# STM32N645 register map
File version: 1.0
CPU: CM55 r0p1, little endian, no MPU, FPU, vendor SysTick, 8 interrupt priority bits
Registers are 32-bit, read-write, reset 0x0 unless marked. A register's access mark holds for its fields unless they carry their own. Offsets are from the block's base; [hi:lo] are bit positions; {n}, {i} and the like mark numbered series; 'fields as' and 'values as' point back to an identical list.

## LPTIM4 — Low-power timer
Base 0x46002C00
Same registers: LPTIM4_S 0x56002C00
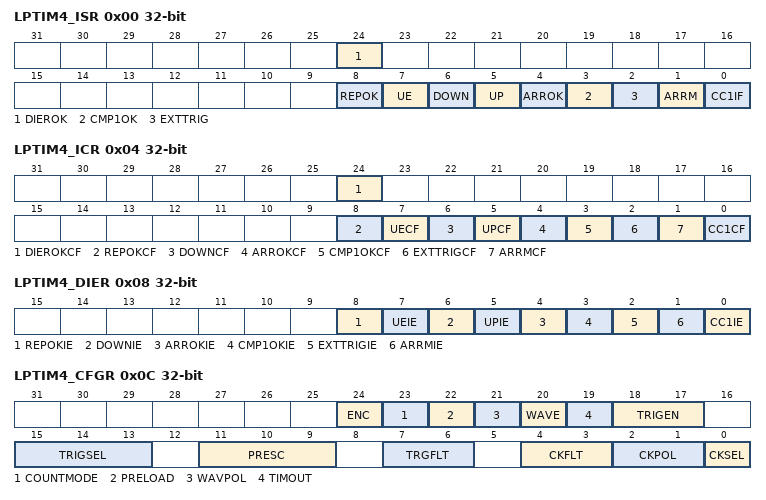
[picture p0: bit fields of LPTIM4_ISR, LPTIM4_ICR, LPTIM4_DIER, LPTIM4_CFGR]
0x00 LPTIM4_ISR ro — LPTIM4 interrupt and status register
  [24] DIEROK — Interrupt enable register update OK
  [8] REPOK — Repetition register update OK
  [7] UE — LPTIM update event occurred
  [6] DOWN — Counter direction change up to down
  [5] UP — Counter direction change down to up
  [4] ARROK — Autoreload register update OK
  [3] CMP1OK — Compare register 1 update OK
  [2] EXTTRIG — External trigger edge event
  [1] ARRM — Autoreload match
  [0] CC1IF — Compare 1 interrupt flag
    0=No match; 1=The content of the counter LPTIM_CNT register value has matched the LPTIM_CCR1 register's value
0x04 LPTIM4_ICR wo — LPTIM4 interrupt clear register
  [24] DIEROKCF — Interrupt enable register update OK clear flag
  [8] REPOKCF — Repetition register update OK clear flag
  [7] UECF — Update event clear flag
  [6] DOWNCF — Direction change to down clear flag
  [5] UPCF — Direction change to UP clear flag
  [4] ARROKCF — Autoreload register update OK clear flag
  [3] CMP1OKCF — Compare register 1 update OK clear flag
  [2] EXTTRIGCF — External trigger valid edge clear flag
  [1] ARRMCF — Autoreload match clear flag
  [0] CC1CF — Capture/compare 1 clear flag
0x08 LPTIM4_DIER — LPTIM4 interrupt enable register
  [8] REPOKIE — Repetition register update OK interrupt Enable
    0=Repetition register update OK interrupt disabled; 1=Repetition register update OK interrupt enabled
  [7] UEIE — Update event interrupt enable
    0=Update event interrupt disabled; 1=Update event interrupt enabled
  [6] DOWNIE — Direction change to down Interrupt Enable
    0=DOWN interrupt disabled; 1=DOWN interrupt enabled
  [5] UPIE — Direction change to UP Interrupt Enable
    0=UP interrupt disabled; 1=UP interrupt enabled
  [4] ARROKIE — Autoreload register update OK Interrupt Enable
    0=ARROK interrupt disabled; 1=ARROK interrupt enabled
  [3] CMP1OKIE — Compare register 1 update OK interrupt enable
    0=CMPOK register 1 interrupt disabled; 1=CMPOK register 1 interrupt enabled
  [2] EXTTRIGIE — External trigger valid edge Interrupt Enable
    0=EXTTRIG interrupt disabled; 1=EXTTRIG interrupt enabled
  [1] ARRMIE — Autoreload match Interrupt Enable
    0=ARRM interrupt disabled; 1=ARRM interrupt enabled
  [0] CC1IE — Capture/compare 1 interrupt enable
    0=Capture/compare 1 interrupt disabled; 1=Capture/compare 1 interrupt enabled
0x0C LPTIM4_CFGR — LPTIM4 configuration register
  [24] ENC — Encoder mode enable
    0=Encoder mode disabled; 1=Encoder mode enabled
  [23] COUNTMODE — counter mode enabled
    0=the counter is incremented following each internal clock pulse; 1=the counter is incremented following each valid clock pulse on the LPTIM external Input1
  [22] PRELOAD — Registers update mode
    0=Registers are updated after each APB bus write access; 1=Registers are updated at the end of the current LPTIM period
  [21] WAVPOL — Waveform shape polarity
    0=The LPTIM output reflects the compare results between LPTIM_CNT and LPTIM_CCRx registers; 1=The LPTIM output reflects the inverse of the compare results between LPTIM_CNT and LPTIM_CCRx registers
  [20] WAVE — Waveform shape
    0=Deactivate Set-once mode; 1=Activate the Set-once mode
  [19] TIMOUT — Timeout enable
    0=A trigger event arriving when the timer is already started is ignored; 1=A trigger event arriving when the timer is already started resets and restarts the LPTIM counter and the repetition counter
  [18:17] TRIGEN — Trigger enable and polarity
    0=software trigger (counting start is initiated by software); 1=rising edge is the active edge; 2=falling edge is the active edge; 3=both edges are active edges
  [15:13] TRIGSEL — Trigger selector
    {v}=lptim_ext_trig{v} (v=0..7)
  [11:9] PRESC — Clock prescaler
    0=/1; 1=/2; 2=/4; 3=/8; 4=/16; 5=/32; 6=/64; 7=/128
  [7:6] TRGFLT — Configurable digital filter for trigger
    0=any trigger active level change is considered as a valid trigger; 1=trigger active level change must be stable for at least 2 clock periods before it is considered as valid trigger; 2=trigger active level change must be stable for at least 4 clock periods before it is considered as valid trigger; 3=trigger active level change must be stable for at least 8 clock periods before it is considered as valid trigger
  [4:3] CKFLT — Configurable digital filter for external clock
    0=any external clock signal level change is considered as a valid transition; 1=external clock signal level change must be stable for at least 2 clock periods before it is considered as valid transition; 2=external clock signal level change must be stable for at least 4 clock periods before it is considered as valid transition; 3=external clock signal level change must be stable for at least 8 clock periods before it is considered as valid transition
  [2:1] CKPOL — Clock Polarity
    0=the rising edge is the active edge used for counting; 1=the falling edge is the active edge used for counting; 2=both edges are active edges. When both external clock signal edges are considered active ones, the LPTIM must also be clocked by an internal clock source with a frequency equal to at least four times the external clock frequency.; 3=not allowed
  [0] CKSEL — Clock selector
    0=LPTIM is clocked by internal clock source (APB clock or any of the embedded oscillators); 1=LPTIM is clocked by an external clock source through the LPTIM external Input1
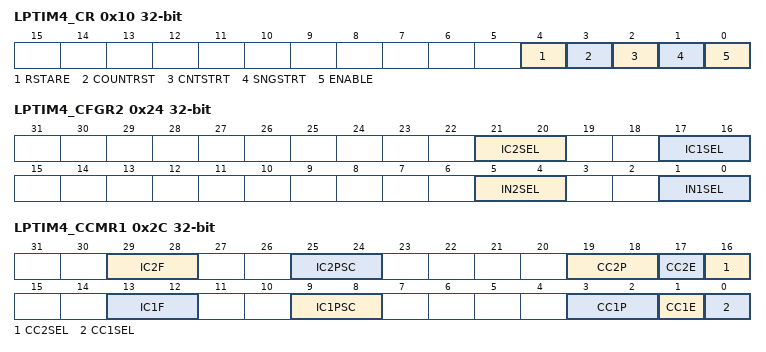
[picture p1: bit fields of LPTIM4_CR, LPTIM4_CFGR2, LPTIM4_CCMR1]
0x10 LPTIM4_CR — LPTIM4 control register
  [4] RSTARE — Reset after read enable
  [3] COUNTRST — Counter reset
  [2] CNTSTRT — Timer start in Continuous mode
  [1] SNGSTRT — LPTIM start in Single mode
  [0] ENABLE — LPTIM enable
    0=LPTIM is disabled. Writing '0' to the ENABLE bit resets all the DMA request signals (input capture and update event DMA requests).; 1=LPTIM is enabled
0x14 LPTIM4_CCR1 — LPTIM4 compare register 1
  [15:0] CCR1 — Capture/compare 1 value
0x18 LPTIM4_ARR reset 0x1 — LPTIM4 autoreload register
  [15:0] ARR — Auto reload value
0x1C LPTIM4_CNT ro — LPTIM4 counter register
  [15:0] CNT — Counter value
0x24 LPTIM4_CFGR2 — LPTIM4 configuration register 2
  [21:20] IC2SEL — LPTIM input capture 2 selection
    {v}=lptim_ic2_mux{v} (v=0..3)
  [17:16] IC1SEL — LPTIM input capture 1 selection
    {v}=lptim_ic1_mux{v} (v=0..3)
  [5:4] IN2SEL — LPTIM input 2 selection
    {v}=lptim_in2_mux{v} (v=0..3)
  [1:0] IN1SEL — LPTIM input 1 selection
    {v}=lptim_in1_mux{v} (v=0..3)
0x28 LPTIM4_RCR — LPTIM4 repetition register
  [7:0] REP — Repetition register value
0x2C LPTIM4_CCMR1 — LPTIM4 capture/compare mode register 1
  [29:28] IC2F — Input capture 2 filter
    0=any external input capture signal level change is considered as a valid transition; 1=external input capture signal level change must be stable for at least 2 clock periods before it is considered as valid transition; 2=external input capture signal level change must be stable for at least 4 clock periods before it is considered as valid transition; 3=external input capture signal level change must be stable for at least 8 clock periods before it is considered as valid transition
  [25:24] IC2PSC — Input capture 2 prescaler
    0=no prescaler, capture is done each time an edge is detected on the capture input; 1=capture is done once every 2 events; 2=capture is done once every 4 events; 3=capture is done once every 8 events
  [19:18] CC2P — Capture/compare 2 output polarity.
    0=B_0x0_CC2_AS_OUTPUT (OC2 active high); 1=B_0x1_CC2_AS_OUTPUT (OC2 active low); 3=B_0x3_CC2_AS_INPUT (both edges, circuit is sensitive to both IC2 rising and falling edges.)
  [17] CC2E — Capture/compare 2 output enable.
    0=B_0x0_CC2_AS_OUTPUT (Off - OC2 is not active. Writing '0' to the CC2E bit resets the ue_dma_req signal only if all the other LPTIM channels are disabled.); 1=B_0x1_CC2_AS_OUTPUT (On - OC2 signal is output on the corresponding output pin)
  [16] CC2SEL — Capture/compare 2 selection
    0=CC2 channel is configured in output PWM mode; 1=CC2 channel is configured in input capture mode
  [13:12] IC1F — Input capture 1 filter
    values as IC2F
  [9:8] IC1PSC — Input capture 1 prescaler
    values as IC2PSC
  [3:2] CC1P — Capture/compare 1 output polarity.
    0=B_0x0_CC1_AS_OUTPUT (OC1 active high, the LPTIM output reflects the compare results between LPTIM_ARR and LPTIM_CCRx registers); 1=B_0x1_CC1_AS_OUTPUT (OC1 active low, the LPTIM output reflects the inverse of the compare results between LPTIM_ARR and LPTIM_CCRx registers); 3=B_0x3_CC1_AS_INPUT (both edges, circuit is sensitive to both IC1 rising and falling edges.)
  [1] CC1E — Capture/compare 1 output enable.
    0=B_0x0_CC1_AS_OUTPUT (Off - OC1 is not active. Writing '0' to the CC1E bit resets the ue_dma_req signal only if all the other LPTIM channels are disabled.); 1=B_0x1_CC1_AS_OUTPUT (On - OC1 signal is output on the corresponding output pin)
  [0] CC1SEL — Capture/compare 1 selection
    0=CC1 channel is configured in output PWM mode; 1=CC1 channel is configured in input capture mode
0x34 LPTIM4_CCR2 — LPTIM4 compare register 2
  [15:0] CCR2 — Capture/compare 2 value

## LPTIM5 — Low-power timer
Base 0x46003000
Same registers: LPTIM5_S 0x56003000
Registers as LPTIM4 (with LPTIM4 read as LPTIM5).
